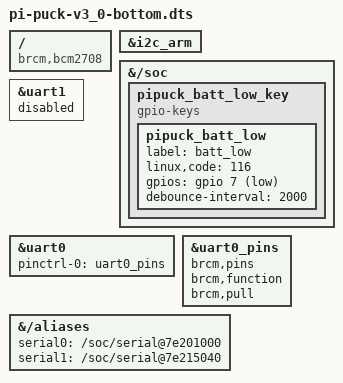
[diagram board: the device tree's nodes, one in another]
/dts-v1/;
/plugin/;

/ {
	compatible = "brcm,bcm2708";

	/* I2C devices */
	fragment@0 {
		target = <&i2c_arm>;
		__overlay__ {
			#address-cells = <1>;
			#size-cells = <0>;
			status = "okay";
			/* e-puck */
			/* FT903 slave */
		};
	};

	/* Batt_low shutdown key */
	fragment@1 {
		target-path = "/soc";
		__overlay__ {
			pipuck_batt_low_key {
				compatible = "gpio-keys";
				pipuck_batt_low: pipuck_batt_low {
					label = "batt_low";
					linux,code = <116>; // KEY_POWER
					gpios = <&gpio 7 1>;
					debounce-interval = <2000>;
				};
			};
		};
	};

	/* Disable Bluetooth to free up UART */
	fragment@2 {
		target = <&uart1>;
		__overlay__ {
			status = "disabled";
		};
	};
	fragment@3 {
		target = <&uart0>;
		__overlay__ {
			pinctrl-names = "default";
			pinctrl-0 = <&uart0_pins>;
			status = "okay";
		};
	};
	fragment@4 {
		target = <&uart0_pins>;
		__overlay__ {
			brcm,pins;
			brcm,function;
			brcm,pull;
		};
	};
	fragment@5 {
		target-path = "/aliases";
		__overlay__ {
			serial0 = "/soc/serial@7e201000";
			serial1 = "/soc/serial@7e215040";
		};
	};

	__overrides__ {
		batt_low_disable = <0>,"-1";
		batt_low_debounce = <&pipuck_batt_low>,"debounce-interval:0";
		uart_disable = <0>,"-2-3-4-5";
	};
};
